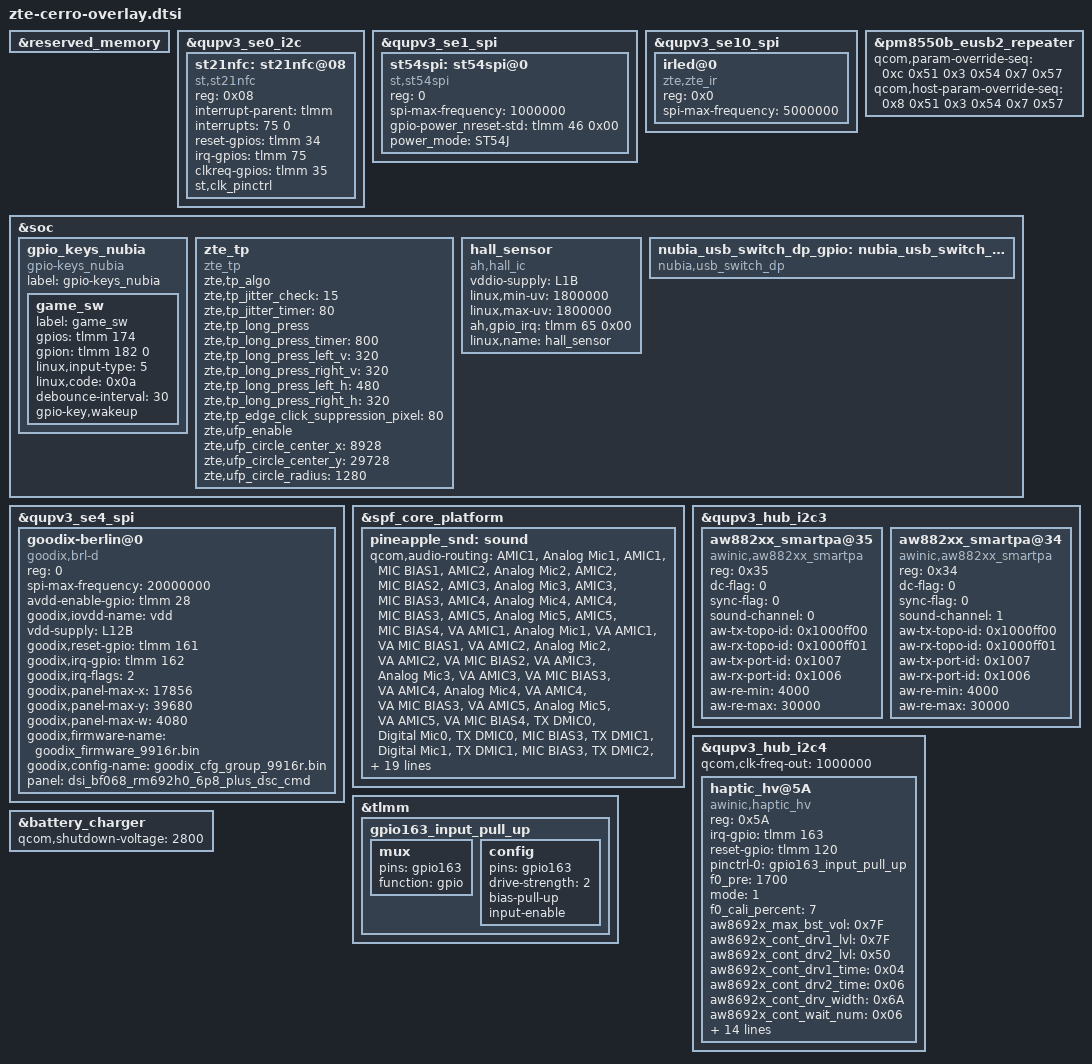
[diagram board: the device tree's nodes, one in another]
/* dtsi for cerro board (PQ83A01)*/
#include <dt-bindings/gpio/gpio.h>
#include <dt-bindings/input/input.h>

&reserved_memory {
};

&qupv3_se0_i2c {
	status = "ok";
	/delete-node/ nq@28;
	st21nfc: st21nfc@08 {
		compatible = "st,st21nfc";
		reg = <0x08>;
		interrupt-parent = <&tlmm>;
		interrupts = <75  0>;
		reset-gpios = <&tlmm 34 0x00>;
		irq-gpios = <&tlmm 75 0x00>;
		// pidle-gpios = <&tlmm 48 0x00>;
		clkreq-gpios = <&tlmm 35 0x00>;
		//clocks = <&clock_rpmh RPMH_RF_CLK3>;
		//clock-names = "nfc_ref_clk";
		st,clk_pinctrl;
		status = "ok";
	};
};

&qupv3_se1_spi {
	status = "ok";
	st54spi: st54spi@0 {
		compatible = "st,st54spi";
		reg = <0>;
		spi-max-frequency = <1000000>;
		/* gpio used as SE_PWR_REQ or SE_nRESET */
		gpio-power_nreset-std = <&tlmm 46 0x00>;

		/* Power management mode: none, ST54H (default), ST54J */
		power_mode = "ST54J";
		status = "ok";
	};
};

&qupv3_se10_spi {
	status = "ok";
	irled@0 {
		status = "ok";
		compatible = "zte,zte_ir";
		reg = <0x0>;
		spi-max-frequency = <5000000>;
	};
};

&pm8550b_eusb2_repeater {
	qcom,param-override-seq =
		/* <value reg_offset> */
		/* Adjust HS trasmit amplitude */
		<0xc 0x51
		/* Squelch detection threshold */
		 0x3 0x54
		/* Tx pre-emphasis tuning */
		 0x7 0x57>;
	qcom,host-param-override-seq =
		/* <value reg_offset> */
		/* Adjust HS trasmit amplitude */
		<0x8 0x51
		/* Squelch detection threshold */
		 0x3 0x54
		/* Tx pre-emphasis tuning */
		 0x7 0x57>;
};

&soc {
    gpio_keys_nubia {
        status = "okay";
        compatible = "gpio-keys_nubia";
        label = "gpio-keys_nubia";
        game_sw {
            label = "game_sw";
            gpios = <&tlmm 174 0>;
            gpion = <&tlmm 182 0>;
            linux,input-type = <5>;
            linux,code = <0x0a>;
            debounce-interval = <30>;
            gpio-key,wakeup;
        };
    };

	zte_tp:zte_tp {
		compatible = "zte_tp";
		zte,tp_algo;
		zte,tp_jitter_check = <15>;
		zte,tp_jitter_timer = <80>;
		zte,tp_long_press;
		zte,tp_long_press_timer = <800>;
		zte,tp_long_press_left_v = <320>;
		zte,tp_long_press_right_v = <320>;
		zte,tp_long_press_left_h = <480>; /*camera */
		zte,tp_long_press_right_h = <320>; /*charger */
		zte,tp_edge_click_suppression_pixel = <80>;
		zte,ufp_enable;
		zte,ufp_circle_center_x = <8928>;
		zte,ufp_circle_center_y = <29728>;
		zte,ufp_circle_radius = <1280>;
	};
	
    hall_sensor {
		compatible = "ah,hall_ic";
		vddio-supply = <&L1B>;
		linux,min-uv = <1800000>;
		linux,max-uv = <1800000>;
		ah,gpio_irq = <&tlmm 65 0x00>;
		linux,name = "hall_sensor";
	};

	nubia_usb_switch_dp_gpio: nubia_usb_switch_dp_gpio_ctrl {
		compatible = "nubia,usb_switch_dp";
		status = "okay";
	};
};

&qupv3_se4_spi {

	status = "ok";

	goodix-berlin@0 {
		compatible = "goodix,brl-d";
		reg = <0>;
		spi-max-frequency = <20000000>;
		avdd-enable-gpio = <&tlmm 28 0x0>;
		goodix,iovdd-name = "vdd";
		vdd-supply = <&L12B>;
		goodix,reset-gpio = <&tlmm 161 0x0>;
		goodix,irq-gpio = <&tlmm 162 0x0>;
		goodix,irq-flags = <2>; /* 1:trigger rising, 2:trigger falling;*/
		goodix,panel-max-x = <17856>;
		goodix,panel-max-y = <39680>;
		goodix,panel-max-w = <4080>;
		goodix,firmware-name = "goodix_firmware_9916r.bin";
		goodix,config-name = "goodix_cfg_group_9916r.bin";
		panel = <&dsi_bf068_rm692h0_6p8_plus_dsc_cmd>;
	};
};

&spf_core_platform  {
	pineapple_snd: sound {
		qcom,audio-routing =
			"AMIC1", "Analog Mic1",
			"AMIC1", "MIC BIAS1",
			"AMIC2", "Analog Mic2",
			"AMIC2", "MIC BIAS2",
			"AMIC3", "Analog Mic3",
			"AMIC3", "MIC BIAS3",
			"AMIC4", "Analog Mic4",
			"AMIC4", "MIC BIAS3",
			"AMIC5", "Analog Mic5",
			"AMIC5", "MIC BIAS4",
			"VA AMIC1", "Analog Mic1",
			"VA AMIC1", "VA MIC BIAS1",
			"VA AMIC2", "Analog Mic2",
			"VA AMIC2", "VA MIC BIAS2",
			"VA AMIC3", "Analog Mic3",
			"VA AMIC3", "VA MIC BIAS3",
			"VA AMIC4", "Analog Mic4",
			"VA AMIC4", "VA MIC BIAS3",
			"VA AMIC5", "Analog Mic5",
			"VA AMIC5", "VA MIC BIAS4",
			"TX DMIC0", "Digital Mic0",
			"TX DMIC0", "MIC BIAS3",
			"TX DMIC1", "Digital Mic1",
			"TX DMIC1", "MIC BIAS3",
			"TX DMIC2", "Digital Mic2",
			"TX DMIC2", "MIC BIAS1",
			"TX DMIC3", "Digital Mic3",
			"TX DMIC3", "MIC BIAS1",
			"IN1_HPHL", "HPHL_OUT",
			"IN2_HPHR", "HPHR_OUT",
			"IN3_EAR", "AUX_OUT",
			"RX_TX DEC0_INP", "TX DEC0 MUX",
			"RX_TX DEC1_INP", "TX DEC1 MUX",
			"RX_TX DEC2_INP", "TX DEC2 MUX",
			"RX_TX DEC3_INP", "TX DEC3 MUX",
			"TX SWR_INPUT", "WCD_TX_OUTPUT",
			"VA SWR_INPUT", "VA_SWR_CLK",
			"VA SWR_INPUT", "WCD_TX_OUTPUT",
			"VA_AIF1 CAP", "VA_SWR_CLK",
			"VA_AIF2 CAP", "VA_SWR_CLK",
			"VA_AIF3 CAP", "VA_SWR_CLK",
			"VA DMIC0", "Digital Mic0",
			"VA DMIC1", "Digital Mic1",
			"VA DMIC2", "Digital Mic2",
			"VA DMIC3", "Digital Mic3",
			"VA DMIC0", "VA MIC BIAS3",
			"VA DMIC1", "VA MIC BIAS3",
			"VA DMIC2", "VA MIC BIAS1",
			"VA DMIC3", "VA MIC BIAS1";
		qcom,msm-mbhc-usbc-audio-supported = <1>;
		qcom,msm-mbhc-hphl-swh = <0>;
		qcom,msm-mbhc-gnd-swh = <0>;
        };
};

&qupv3_hub_i2c3 {
	status = "okay";
	/* AWINIC AW882XX Smart PA */
	aw882xx_smartpa@35 {
		compatible = "awinic,aw882xx_smartpa";
		reg = <0x35>;
		dc-flag = <0>;
		sync-flag = <0>;
		sound-channel = <0>;
		aw-tx-topo-id = <0x1000ff00>;
		aw-rx-topo-id = <0x1000ff01>;
		aw-tx-port-id = <0x1007>;
		aw-rx-port-id = <0x1006>;
		aw-re-min = <4000>;
		aw-re-max= <30000>;
		/*aw-cali-mode = "none";*/
	};
	aw882xx_smartpa@34 {
		compatible = "awinic,aw882xx_smartpa";
		reg = <0x34>;
		dc-flag = <0>;
		sync-flag = <0>;
		sound-channel = <1>;
		aw-tx-topo-id = <0x1000ff00>;
		aw-rx-topo-id = <0x1000ff01>;
		aw-tx-port-id = <0x1007>;
		aw-rx-port-id = <0x1006>;
		aw-re-min = <4000>;
		aw-re-max= <30000>;
		/*aw-cali-mode = "none";*/
	};
};
	/* AWINIC AW882XX Smart PA End */

/* add zte haptic start */
&qupv3_hub_i2c4 {
	status = "ok";
	qcom,clk-freq-out = <1000000>;
	haptic_hv@5A {
		compatible = "awinic,haptic_hv";
		reg = <0x5A>;
		irq-gpio = <&tlmm 163 0>;
		reset-gpio = <&tlmm 120 0>;
		pinctrl-names = "irq_active";
		pinctrl-0 = <&gpio163_input_pull_up>;
		f0_pre = < 1700 >;
		mode = /bits/ 8 < 1 >;
		f0_cali_percent = /bits/ 8 < 7 >;
/******************************aw8692x*******************************/
		aw8692x_max_bst_vol = /bits/ 8 < 0x7F >;
		aw8692x_cont_drv1_lvl = /bits/ 8 < 0x7F >;
		aw8692x_cont_drv2_lvl = /bits/ 8 < 0x50 >;
		aw8692x_cont_drv1_time = /bits/ 8 < 0x04 >;
		aw8692x_cont_drv2_time = /bits/ 8 < 0x06 >;
		aw8692x_cont_drv_width = /bits/ 8 < 0x6A >;
		aw8692x_cont_wait_num = /bits/ 8 < 0x06 >;
		aw8692x_cont_brk_time = /bits/ 8 < 0 >;
		aw8692x_cont_track_margin = /bits/ 8 < 0x0C >;
		aw8692x_brk_bst_md = /bits/ 8 < 0 >;
		aw8692x_cont_tset = /bits/ 8 < 0x06 >;
		aw8692x_cont_bemf_set = /bits/ 8 < 0x02 >;
		aw8692x_cont_bst_brk_gain = /bits/ 8 < 0x05 >;
		aw8692x_cont_brk_gain = /bits/ 8 < 0x08 >;
		aw8692x_duration_time = /bits/ 8 < 20 30 60 >;
		aw8692x_d2s_gain = /bits/ 8 < 0x04 >;
		aw8692x_trig_config = /bits/ 8 < 0 0 0 1 0 2 0 0
						 0 0 0 1 0 2 0 0
						 0 0 0 1 0 2 0 0 >;
		aw8692x_bst_vol_default = /bits/ 8 < 0x50 >;
		aw8692x_bst_vol_ram = /bits/ 8 < 0x50 >;
		aw8692x_bst_vol_rtp = /bits/ 8 < 0x50 >;
		/* aw8692x_is_enabled_auto_bst; */
		/* aw8692x_is_enabled_one_wire; */
	};
};

&tlmm {
	gpio163_input_pull_up: gpio163_input_pull_up {
		mux {
			 pins = "gpio163";
			 function = "gpio";
		};

		config {
			pins = "gpio163";
			drive-strength = <2>;
			bias-pull-up;
			input-enable;
		};
	};
};

&battery_charger {
	qcom,shutdown-voltage = <2800>;
};
